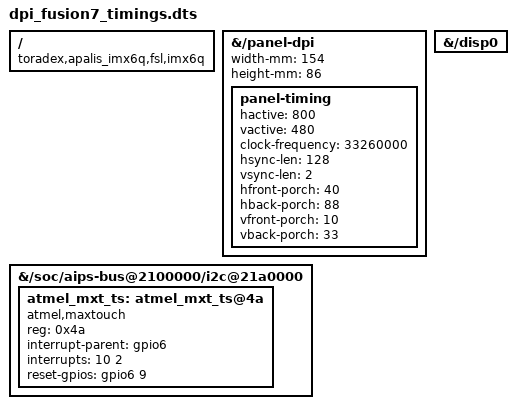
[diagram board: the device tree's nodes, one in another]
/dts-v1/;
/plugin/;

/ {
  compatible = "toradex,apalis_imx6q,fsl,imx6q";
  fragment@0 {
    target-path = "/panel-dpi";
    __overlay__ {
      width-mm = <154>;
      height-mm = <86>;
    	panel-timing {
    		hactive = <800>;
    		vactive = <480>;
        clock-frequency = <33260000>;
        hsync-len = <128>;
        vsync-len = <2>;
        hfront-porch = <40>;
        hback-porch = <88>;
        vfront-porch = <10>;
        vback-porch = <33>;
    	};
    };
  };

  fragment@1 {
  	target-path="/disp0";
  	__overlay__ {
  		status="okay";
  	};
  };
  fragment@2 {
    target-path="/soc/aips-bus@2100000/i2c@21a0000";
    __overlay__ {
      status = "okay";
      atmel_mxt_ts: atmel_mxt_ts@4a {
        compatible = "atmel,maxtouch";
        reg = <0x4a>;
        interrupt-parent = <&gpio6>;
        interrupts = <10 2>;
        reset-gpios = <&gpio6 9 0>;
        status = "okay";
      };
    };
  };
};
